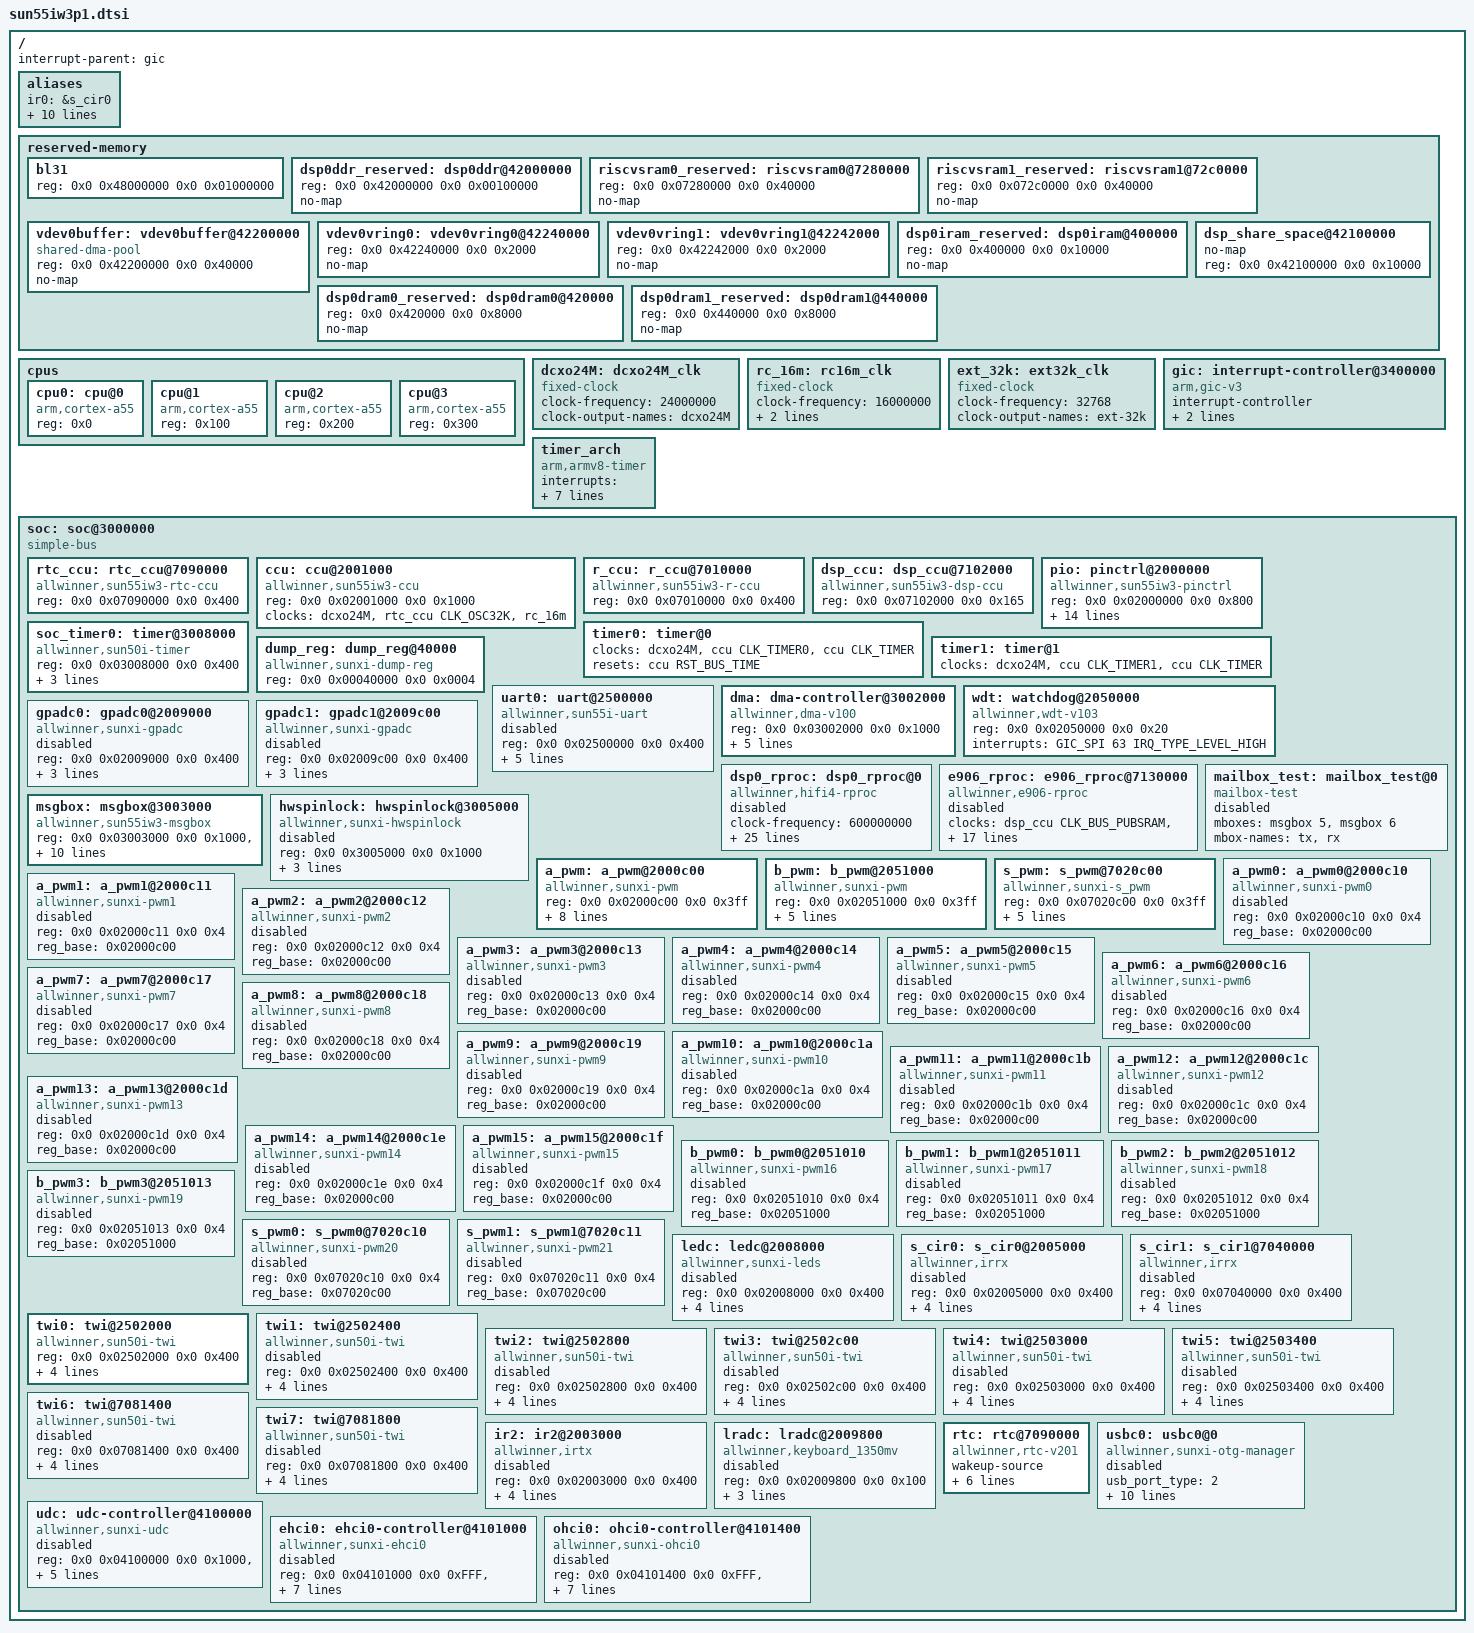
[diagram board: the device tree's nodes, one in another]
// SPDX-License-Identifier: (GPL-2.0+ or MIT)
/*
 * Copyright (C) 2021 liujuan1@allwinnertech.com
 */

#include <dt-bindings/clock/sun55iw3-ccu.h>
#include <dt-bindings/clock/sun55iw3-rtc.h>
#include <dt-bindings/clock/sun55iw3-r-ccu.h>
#include <dt-bindings/clock/sun55iw3-dsp-ccu.h>
#include <dt-bindings/gpio/gpio.h>
#include <dt-bindings/interrupt-controller/arm-gic.h>
#include <dt-bindings/reset/sun55iw3-ccu.h>
#include <dt-bindings/reset/sun55iw3-r-ccu.h>
#include <dt-bindings/reset/sun55iw3-dsp-ccu.h>

/ {
	interrupt-parent = <&gic>;
	#address-cells = <2>;
	#size-cells = <2>;

	aliases {
		ir0 = &s_cir0;
		ir1 = &s_cir1;
		ir2 = &ir2;
		twi0 = &twi0;
		twi1 = &twi1;
		twi2 = &twi2;
		twi3 = &twi3;
		twi4 = &twi4;
		twi5 = &twi5;
		twi6 = &twi6;
		twi7 = &twi7;
	};

	reserved-memory {
		#address-cells = <2>;
		#size-cells = <2>;
		ranges;

		bl31 {
			reg = <0x0 0x48000000 0x0 0x01000000>;
		};

		dsp0ddr_reserved: dsp0ddr@42000000 {
			reg = <0x0 0x42000000 0x0 0x00100000>;
			no-map;
		};

		riscvsram0_reserved: riscvsram0@7280000 {
			reg = <0x0 0x07280000 0x0 0x40000>;
			no-map;
		};

		riscvsram1_reserved: riscvsram1@72c0000 {
			reg = <0x0 0x072c0000 0x0 0x40000>;
			no-map;
		};

		/*
		 * The name should be "vdev%dbuffer".
		 * Its size should be not less than
		 *     RPMSG_BUF_SIZE * (num of buffers in a vring) * 2
		 *   = 512 * (num of buffers in a vring) * 2
		 */
		vdev0buffer: vdev0buffer@42200000 {
			compatible = "shared-dma-pool";
			reg = <0x0 0x42200000 0x0 0x40000>;
			no-map;
		};

		/*
		 * The name should be "vdev%dvring%d".
		 * The size of each should be not less than
		 *     PAGE_ALIGN(vring_size(num, align))
		 *   = PAGE_ALIGN(16 * num + 6 + 2 * num + (pads for align) + 6 + 8 * num)
		 *
		 * (Please refer to the vring layout in include/uapi/linux/virtio_ring.h)
		 */
		vdev0vring0: vdev0vring0@42240000 {
			reg = <0x0 0x42240000 0x0 0x2000>;
			no-map;
		};
		vdev0vring1: vdev0vring1@42242000 {
			reg = <0x0 0x42242000 0x0 0x2000>;
			no-map;
		};

		/*
		* dsp ram addr
		*/
		dsp0iram_reserved: dsp0iram@400000 {
			reg = <0x0 0x400000 0x0 0x10000>;
			no-map;
		};
		dsp0dram0_reserved: dsp0dram0@420000 {
			reg = <0x0 0x420000 0x0 0x8000>;
			no-map;
		};
		dsp0dram1_reserved: dsp0dram1@440000 {
			reg = <0x0 0x440000 0x0 0x8000>;
			no-map;
		};

		dsp_share_space@42100000 {
			no-map;
			reg = <0x0 0x42100000 0x0 0x10000>;
		};
	};

	cpus {
		#address-cells = <1>;
		#size-cells = <0>;

		cpu0: cpu@0 {
			device_type = "cpu";
			compatible = "arm,cortex-a55";
			reg = <0x0>;
		};

		cpu@1 {
			device_type = "cpu";
			compatible = "arm,cortex-a55";
			reg = <0x100>;
		};

		cpu@2 {
			device_type = "cpu";
			compatible = "arm,cortex-a55";
			reg = <0x200>;
		};

		cpu@3 {
			device_type = "cpu";
			compatible = "arm,cortex-a55";
			reg = <0x300>;
		};
	};

	dcxo24M: dcxo24M_clk {
		#clock-cells = <0>;
		compatible = "fixed-clock";
		clock-frequency = <24000000>;
		clock-output-names = "dcxo24M";
	};

	rc_16m: rc16m_clk {
		#clock-cells = <0>;
		compatible = "fixed-clock";
		clock-frequency = <16000000>;
		clock-accuracy = <300000000>;
		clock-output-names = "rc-16m";
	};

	ext_32k: ext32k_clk {
		#clock-cells = <0>;
		compatible = "fixed-clock";
		clock-frequency = <32768>;
		clock-output-names = "ext-32k";
	};

	gic: interrupt-controller@3400000 {
		compatible = "arm,gic-v3";
		#interrupt-cells = <3>;
		#address-cells = <0>;
		interrupt-controller;
		reg = <0x0 0x03400000 0 0x10000>, /* GIC Dist */
		      <0x0 0x03460000 0 0xFF004>; /* GIC Re */
	};

	timer_arch {
		compatible = "arm,armv8-timer";
		interrupts = <GIC_PPI 13 (GIC_CPU_MASK_SIMPLE(4) | IRQ_TYPE_LEVEL_LOW)>,
			   <GIC_PPI 14 (GIC_CPU_MASK_SIMPLE(4) | IRQ_TYPE_LEVEL_LOW)>,
			   <GIC_PPI 11 (GIC_CPU_MASK_SIMPLE(4) | IRQ_TYPE_LEVEL_LOW)>,
			   <GIC_PPI 10 (GIC_CPU_MASK_SIMPLE(4) | IRQ_TYPE_LEVEL_LOW)>;
		clock-frequency = <24000000>;
		interrupt-parent = <&gic>;
		arm,no-tick-in-suspend;
	};

	soc: soc@3000000 {
		compatible = "simple-bus";
		#address-cells = <2>;
		#size-cells = <2>;
		ranges;

		rtc_ccu: rtc_ccu@7090000 {
			compatible = "allwinner,sun55iw3-rtc-ccu";
			reg = <0x0 0x07090000 0x0 0x400>;
			#clock-cells = <1>;
			#reset-cells = <1>;
		};

		ccu: ccu@2001000 {
			compatible = "allwinner,sun55iw3-ccu";
			reg = <0x0 0x02001000 0x0 0x1000>;
			clocks = <&dcxo24M>, <&rtc_ccu CLK_OSC32K>, <&rc_16m>;
			clock-names = "hosc", "losc", "iosc";
			#clock-cells = <1>;
			#reset-cells = <1>;
		};

		r_ccu: r_ccu@7010000 {
			compatible = "allwinner,sun55iw3-r-ccu";
			reg = <0x0 0x07010000 0x0 0x400>;
			#clock-cells = <1>;
			#reset-cells = <1>;
		};

		dsp_ccu: dsp_ccu@7102000 {
			compatible = "allwinner,sun55iw3-dsp-ccu";
			reg = <0x0 0x07102000 0x0 0x165>;
			#clock-cells = <1>;
			#reset-cells = <1>;
		};

		pio: pinctrl@2000000 {
			compatible = "allwinner,sun55iw3-pinctrl";
			reg = <0x0 0x02000000 0x0 0x800>;
			interrupts = <GIC_SPI 67 IRQ_TYPE_LEVEL_HIGH>,
				     <GIC_SPI 69 IRQ_TYPE_LEVEL_HIGH>,
				     <GIC_SPI 71 IRQ_TYPE_LEVEL_HIGH>,
				     <GIC_SPI 73 IRQ_TYPE_LEVEL_HIGH>,
				     <GIC_SPI 75 IRQ_TYPE_LEVEL_HIGH>,
				     <GIC_SPI 77 IRQ_TYPE_LEVEL_HIGH>,
				     <GIC_SPI 79 IRQ_TYPE_LEVEL_HIGH>,
				     <GIC_SPI 81 IRQ_TYPE_LEVEL_HIGH>,
				     <GIC_SPI 83 IRQ_TYPE_LEVEL_HIGH>,
				     <GIC_SPI 85 IRQ_TYPE_LEVEL_HIGH>;
			clocks = <&ccu CLK_APB1>, <&dcxo24M>, <&rtc_ccu CLK_OSC32K>;
			clock-names = "apb", "hosc", "losc";
			gpio-controller;
			#gpio-cells = <3>;
			interrupt-controller;
			#interrupt-cells = <3>;

		};

		soc_timer0: timer@3008000 {
			compatible = "allwinner,sun50i-timer";
			device_type = "soc_timer";
			reg = <0x0 0x03008000 0x0 0x400>;
			interrupt-parent = <&gic>;
			interrupts = <GIC_SPI 55 IRQ_TYPE_LEVEL_HIGH>;
			sunxi-timers = <&timer0>, <&timer1>;
		};

		timer0: timer@0 {
			clocks = <&dcxo24M>, <&ccu CLK_TIMER0>, <&ccu CLK_TIMER>;
			clock-names = "parent", "mod", "bus";
			resets = <&ccu RST_BUS_TIME>;
		};

		timer1: timer@1 {
			clocks = <&dcxo24M>, <&ccu CLK_TIMER1>, <&ccu CLK_TIMER>;
			clock-names = "parent", "mod", "bus";
		};

		dump_reg:dump_reg@40000 {
			 compatible = "allwinner,sunxi-dump-reg";
			 reg = <0x0 0x00040000 0x0 0x0004>;
		};

		uart0: uart@2500000 {
			compatible = "allwinner,sun55i-uart";
			reg = <0x0 0x02500000 0x0 0x400>;
			interrupts = <GIC_SPI 2 IRQ_TYPE_LEVEL_HIGH>;
			clocks = <&ccu CLK_BUS_UART0>;
			resets = <&ccu RST_BUS_UART0>;
			uart0_port = <0>;
			uart0_type = <2>;
			status = "disabled";
		};

		dma:dma-controller@3002000 {
			compatible = "allwinner,dma-v100";
			reg = <0x0 0x03002000 0x0 0x1000>;
			interrupts = <GIC_SPI 50 IRQ_TYPE_LEVEL_HIGH>;
			clocks = <&ccu CLK_DMA>, <&ccu CLK_DMA_MBUS_GATE>;
			clock-names = "bus", "mbus";
			dma-channels = <16>;
			dma-requests = <54>;
			resets = <&ccu RST_BUS_DMA>;
			#dma-cells = <1>;
		};

		wdt: watchdog@2050000 {
			compatible = "allwinner,wdt-v103";
			reg = <0x0 0x02050000 0x0 0x20>;  /* In Timers Spec */
			interrupts = <GIC_SPI 63 IRQ_TYPE_LEVEL_HIGH>;  /* In GIC Spec */
		};

		gpadc0: gpadc0@2009000 {
			compatible = "allwinner,sunxi-gpadc";
			reg = <0x0 0x02009000 0x0 0x400>;
			interrupts = <GIC_SPI 61 IRQ_TYPE_LEVEL_HIGH>;
			clocks = <&ccu CLK_BUS_GPADC0>;
			clock-names = "bus";
			resets = <&ccu RST_BUS_GPADC0>;
			status = "disabled";
		};

		gpadc1: gpadc1@2009c00 {
			compatible = "allwinner,sunxi-gpadc";
			reg = <0x0 0x02009c00 0x0 0x400>;
			interrupts = <GIC_SPI 64 IRQ_TYPE_LEVEL_HIGH>;
			clocks = <&ccu CLK_BUS_GPADC1>;
			clock-names = "bus";
			resets = <&ccu RST_BUS_GPADC1>;
			status = "disabled";
		};

		dsp0_rproc: dsp0_rproc@0 {
			compatible = "allwinner,hifi4-rproc";
			clock-frequency = <600000000>;
			clocks = <&ccu CLK_PLL_PERI0_2X>, <&ccu CLK_DSP>, <&dsp_ccu CLK_BUS_DSP_CFG>, <&r_ccu CLK_R_AHB>;
			clock-names = "pll", "mod", "cfg", "ahbs";
			resets = <&dsp_ccu RST_BUS_DSP>, <&dsp_ccu RST_BUS_DSP_CFG>, <&dsp_ccu RST_BUS_DSP_DBG>;
			reset-names = "mod-rst", "cfg-rst", "dbg-rst";
			reg = <0x0 0x07010364 0x0 0x04>,
				<0x0 0x07100000 0x0 0x40>;
			reg-names = "sram-for-cpux", "hifi4-cfg";
			mboxes = <&msgbox 4>;
			mbox-names = "arm-kick";
			memory-region = <&dsp0ddr_reserved>, <&vdev0buffer>, <&vdev0vring0>, <&vdev0vring1>,
					<&dsp0iram_reserved>, <&dsp0dram0_reserved>, <&dsp0dram1_reserved>;
			memory-mappings =
				/* < DA		len		PA >	*/
				/* local SRAM via external bus */
				< 0x20000	0x20000		0x20000 >,
				/* local SRAM via internal bus */
				< 0x400000	0x10000		0x400000 >,
				< 0x420000	0x8000		0x420000 >,
				< 0x440000	0x8000		0x440000 >,
				/* DDR front 256MB */
				< 0x10000000	0x10000000	0x40000000 >,
				/* local SRAM via internal bus */
				< 0x20020000	0x10000		0x400000 >,
				< 0x20030000	0x8000		0x420000 >,
				< 0x20038000	0x8000		0x440000 >,

				/* DDR front 256MB */
				< 0x30000000	0x10000000	0x40000000 >,
				/* DDR front 1GB */
				< 0x40000000	0x40000000	0x40000000 >,
				/* DDR front 1GB */
				< 0x80000000	0x40000000	0x40000000 >,
				/* DDR front 1GB */
				< 0xC0000000	0x40000000	0x40000000 >;
			id = <0>;
			status = "disabled";
		};

		e906_rproc: e906_rproc@7130000 {
			compatible = "allwinner,e906-rproc";
			clocks = <&dsp_ccu CLK_BUS_PUBSRAM>, <&dsp_ccu CLK_BUS_RV>, <&dsp_ccu CLK_BUS_RV_CFG>;
			clock-names = "pubsram", "mod", "cfg";
			resets = <&dsp_ccu RST_BUS_PUBSRAM>, <&dsp_ccu RST_BUS_RV>, <&dsp_ccu RST_BUS_RV_CFG>, <&dsp_ccu RST_BUS_RV_DBG>;
			reset-names = "pubsram-rst", "mod-rst", "cfg-rst", "dbg-rst";
			reg = <0x0 0x07130000 0x0 0x1000>;
			reg-names = "e906-cfg";
			mboxes = <&msgbox 8>;
			mbox-names = "arm-kick";
			memory-region = <&riscvsram0_reserved>, <&riscvsram1_reserved>, <&vdev0buffer>, <&vdev0vring0>, <&vdev0vring1>;
			memory-mappings =
				/* < DA		len		PA >	*/
				/* DSP RAM */
				< 0x20000	0x20000		0x20000 >,
				/* SRAM A2 */
				< 0x40000	0x24000		0x40000 >,
				/* DDR */
				< 0x8000000	0x37f00000	0x8000000 >,
				/* SRAM SPACE 0 */
				< 0x3ffc0000	0x40000		0x07280000 >,
				/* SRAM SPACE 1 */
				< 0x40000000	0x40000		0x072c0000 >,
				/* DRAM SPACE */
				< 0x40040000	0x3ffc0000	0x40040000>;
			id = <0>;
			status = "disabled";
		};

		/* test for AMP mailbox */
		mailbox_test: mailbox_test@0 {
			compatible = "mailbox-test";
			mboxes = <&msgbox 5>, <&msgbox 6>;
			mbox-names = "tx", "rx";
			status = "disabled";
		};

		/*
		* Some bitfile doesn't have riscv part.
		* When use such bitfile, remember to delete
		* riscv reg and irq in msgbox dts node,
		* otherwise may cause Linux stuck.
		* In the same time, adjust sun55iw3 hwdata's
		* processors_max to 3, and mbox_num_chans to 8
		* in msgbox driver.
		*/
		msgbox: msgbox@3003000 {
			compatible = "allwinner,sun55iw3-msgbox";
			#mbox-cells = <1>;
			reg = <0x0 0x03003000 0x0 0x1000>,
			      <0x0 0x07120000 0x0 0x1000>,
			      <0x0 0x07094000 0x0 0x1000>,
			      <0x0 0x07136000 0x0 0x1000>;
			interrupts = <GIC_SPI 0 IRQ_TYPE_LEVEL_HIGH>,
					<GIC_SPI 1 IRQ_TYPE_LEVEL_HIGH>,
					<GIC_SPI 181 IRQ_TYPE_LEVEL_HIGH>,
					<GIC_SPI 174 IRQ_TYPE_LEVEL_HIGH>;
			clocks = <&ccu CLK_MSGBOX0>;
			resets = <&ccu RST_BUS_MSGBOX0>;
			reset-names = "rst";
			local_id = <0>;
		};

		hwspinlock: hwspinlock@3005000 {
			compatible = "allwinner,sunxi-hwspinlock";
			reg = <0x0 0x3005000 0x0 0x1000>;
			#hwlock-cells = <1>;
			clocks = <&ccu CLK_SPINLOCK>;
			clock-names = "clk_hwspinlock_bus";
			resets = <&ccu RST_BUS_SPINLOCK>;
			reset-names = "rst";
			num-locks = <32>;
			status = "disabled";
		};

		a_pwm: a_pwm@2000c00 {
			#pwm-cells = <0x3>;
			compatible = "allwinner,sunxi-pwm";
			reg = <0x0 0x02000c00 0x0 0x3ff>;
			clocks = <&ccu CLK_PWM>;
			resets = <&ccu RST_BUS_PWM>;
			pwm-number = <16>;
			pwm-base = <0x0>;
			sunxi-pwms = <&a_pwm0>, <&a_pwm1>, <&a_pwm2>, <&a_pwm3>, <&a_pwm4>,
			<&a_pwm5>, <&a_pwm6>, <&a_pwm7>, <&a_pwm8>, <&a_pwm9>,
			<&a_pwm10>, <&a_pwm11>, <&a_pwm12>, <&a_pwm13>,
			<&a_pwm14>, <&a_pwm15>;
		};

		b_pwm: b_pwm@2051000 {
			#pwm-cells = <0x3>;
			compatible = "allwinner,sunxi-pwm";
			reg = <0x0 0x02051000 0x0 0x3ff>;
			clocks = <&ccu CLK_PWM1>;
			resets = <&ccu RST_BUS_PWM1>;
			pwm-number = <4>;
			pwm-base = <0x10>;
			sunxi-pwms = <&b_pwm0>, <&b_pwm1>, <&b_pwm2>, <&b_pwm3>;
		};

		s_pwm: s_pwm@7020c00 {
			#pwm-cells = <0x3>;
			compatible = "allwinner,sunxi-s_pwm";
			reg = <0x0 0x07020c00 0x0 0x3ff>;
			clocks = <&r_ccu CLK_R_PWM>;
			resets = <&r_ccu RST_R_PWM>;
			pwm-number = <2>;
			pwm-base = <0x20>;
			sunxi-pwms = <&s_pwm0>, <&s_pwm1>;
		};

		a_pwm0: a_pwm0@2000c10 {
			compatible = "allwinner,sunxi-pwm0";
			pinctrl-names = "active", "sleep";
			reg = <0x0 0x02000c10 0x0 0x4>;
			reg_base = <0x02000c00>;
			status = "disabled";
		};

		a_pwm1: a_pwm1@2000c11 {
			compatible = "allwinner,sunxi-pwm1";
			pinctrl-names = "active", "sleep";
			reg = <0x0 0x02000c11 0x0 0x4>;
			reg_base = <0x02000c00>;
			status = "disabled";
		};

		a_pwm2: a_pwm2@2000c12 {
			compatible = "allwinner,sunxi-pwm2";
			pinctrl-names = "active", "sleep";
			reg = <0x0 0x02000c12 0x0 0x4>;
			reg_base = <0x02000c00>;
			status = "disabled";
		};

		a_pwm3: a_pwm3@2000c13 {
			compatible = "allwinner,sunxi-pwm3";
			pinctrl-names = "active", "sleep";
			reg = <0x0 0x02000c13 0x0 0x4>;
			reg_base = <0x02000c00>;
			status = "disabled";
		};

		a_pwm4: a_pwm4@2000c14 {
			compatible = "allwinner,sunxi-pwm4";
			pinctrl-names = "active", "sleep";
			reg = <0x0 0x02000c14 0x0 0x4>;
			reg_base = <0x02000c00>;
			status = "disabled";
		};

		a_pwm5: a_pwm5@2000c15 {
			compatible = "allwinner,sunxi-pwm5";
			pinctrl-names = "active", "sleep";
			reg = <0x0 0x02000c15 0x0 0x4>;
			reg_base = <0x02000c00>;
			status = "disabled";
		};

		a_pwm6: a_pwm6@2000c16 {
			compatible = "allwinner,sunxi-pwm6";
			pinctrl-names = "active", "sleep";
			reg = <0x0 0x02000c16 0x0 0x4>;
			reg_base = <0x02000c00>;
			status = "disabled";
		};

		a_pwm7: a_pwm7@2000c17 {
			compatible = "allwinner,sunxi-pwm7";
			pinctrl-names = "active", "sleep";
			reg = <0x0 0x02000c17 0x0 0x4>;
			reg_base = <0x02000c00>;
			status = "disabled";
		};

		a_pwm8: a_pwm8@2000c18 {
			compatible = "allwinner,sunxi-pwm8";
			pinctrl-names = "active", "sleep";
			reg = <0x0 0x02000c18 0x0 0x4>;
			reg_base = <0x02000c00>;
			status = "disabled";
		};

		a_pwm9: a_pwm9@2000c19 {
			compatible = "allwinner,sunxi-pwm9";
			pinctrl-names = "active", "sleep";
			reg = <0x0 0x02000c19 0x0 0x4>;
			reg_base = <0x02000c00>;
			status = "disabled";
		};

		a_pwm10: a_pwm10@2000c1a {
			compatible = "allwinner,sunxi-pwm10";
			pinctrl-names = "active", "sleep";
			reg = <0x0 0x02000c1a 0x0 0x4>;
			reg_base = <0x02000c00>;
			status = "disabled";
		};

		a_pwm11: a_pwm11@2000c1b {
			compatible = "allwinner,sunxi-pwm11";
			pinctrl-names = "active", "sleep";
			reg = <0x0 0x02000c1b 0x0 0x4>;
			reg_base = <0x02000c00>;
			status = "disabled";
		};

		a_pwm12: a_pwm12@2000c1c {
			compatible = "allwinner,sunxi-pwm12";
			pinctrl-names = "active", "sleep";
			reg = <0x0 0x02000c1c 0x0 0x4>;
			reg_base = <0x02000c00>;
			status = "disabled";
		};

		a_pwm13: a_pwm13@2000c1d {
			compatible = "allwinner,sunxi-pwm13";
			pinctrl-names = "active", "sleep";
			reg = <0x0 0x02000c1d 0x0 0x4>;
			reg_base = <0x02000c00>;
			status = "disabled";
		};

		a_pwm14: a_pwm14@2000c1e {
			compatible = "allwinner,sunxi-pwm14";
			pinctrl-names = "active", "sleep";
			reg = <0x0 0x02000c1e 0x0 0x4>;
			reg_base = <0x02000c00>;
			status = "disabled";
		};

		a_pwm15: a_pwm15@2000c1f {
			compatible = "allwinner,sunxi-pwm15";
			pinctrl-names = "active", "sleep";
			reg = <0x0 0x02000c1f 0x0 0x4>;
			reg_base = <0x02000c00>;
			status = "disabled";
		};

		b_pwm0: b_pwm0@2051010 {
			compatible = "allwinner,sunxi-pwm16";
			pinctrl-names = "active", "sleep";
			reg = <0x0 0x02051010 0x0 0x4>;
			reg_base = <0x02051000>;
			status = "disabled";
		};

		b_pwm1: b_pwm1@2051011 {
			compatible = "allwinner,sunxi-pwm17";
			pinctrl-names = "active", "sleep";
			reg = <0x0 0x02051011 0x0 0x4>;
			reg_base = <0x02051000>;
			status = "disabled";
		};

		b_pwm2: b_pwm2@2051012 {
			compatible = "allwinner,sunxi-pwm18";
			pinctrl-names = "active", "sleep";
			reg = <0x0 0x02051012 0x0 0x4>;
			reg_base = <0x02051000>;
			status = "disabled";
		};

		b_pwm3: b_pwm3@2051013 {
			compatible = "allwinner,sunxi-pwm19";
			pinctrl-names = "active", "sleep";
			reg = <0x0 0x02051013 0x0 0x4>;
			reg_base = <0x02051000>;
			status = "disabled";
		};

		s_pwm0: s_pwm0@7020c10 {
			compatible = "allwinner,sunxi-pwm20";
			pinctrl-names = "active", "sleep";
			reg = <0x0 0x07020c10 0x0 0x4>;
			reg_base = <0x07020c00>;
			status = "disabled";
		};

		s_pwm1: s_pwm1@7020c11 {
			compatible = "allwinner,sunxi-pwm21";
			pinctrl-names = "active", "sleep";
			reg = <0x0 0x07020c11 0x0 0x4>;
			reg_base = <0x07020c00>;
			status = "disabled";
		};

		ledc: ledc@2008000 {
			#address-cells = <1>;
			#size-cells = <0>;
			compatible = "allwinner,sunxi-leds";
			reg = <0x0 0x02008000 0x0 0x400>;
			interrupts = <GIC_SPI 28 IRQ_TYPE_LEVEL_HIGH>;
			clocks = <&ccu CLK_LEDC>, <&ccu CLK_BUS_LEDC>;
			clock-names = "clk_ledc", "clk_cpuapb";
			resets = <&ccu RST_BUS_LEDC>;
			reset-names = "ledc_reset";
			dmas = <&dma 42>, <&dma 42>;
			dma-names = "rx", "tx";
			status = "disabled";
		};

		s_cir0: s_cir0@2005000 {
			compatible = "allwinner,irrx";
			reg = <0x0 0x02005000 0x0 0x400>;
			interrupts = <GIC_SPI 27 IRQ_TYPE_LEVEL_HIGH>;
			clocks = <&ccu CLK_BUS_IRRX>, <&dcxo24M>, <&ccu CLK_IRRX>;
			clock-names = "bus", "pclk", "mclk";
			resets = <&ccu RST_BUS_IRRX>;
			status = "disabled";
		};

		s_cir1: s_cir1@7040000 {
			compatible = "allwinner,irrx";
			reg = <0x0 0x07040000 0x0 0x400>;
			interrupts = <GIC_SPI 167 IRQ_TYPE_LEVEL_HIGH>;
			clocks = <&r_ccu CLK_BUS_R_IRRX>, <&dcxo24M>, <&r_ccu CLK_R_IRRX>;
			clock-names = "bus", "pclk", "mclk";
			resets = <&r_ccu RST_R_IRRX>;
			status = "disabled";
		};

		twi0: twi@2502000 {
			#address-cells = <1>;
			#size-cells = <0>;
			compatible = "allwinner,sun50i-twi";
			device_type = "twi0";
			reg = <0x0 0x02502000 0x0 0x400>;
			interrupts = <GIC_SPI 10 IRQ_TYPE_LEVEL_HIGH>;
			clocks = <&ccu CLK_TWI0>;
			clock-names = "bus";
			resets = <&ccu RST_BUS_TWI0>;
			dmas = <&dma 43>, <&dma 43>;
			dma-names = "tx", "rx";
			status = "okay";
		};

		twi1: twi@2502400 {
			#address-cells = <1>;
			#size-cells = <0>;
			compatible = "allwinner,sun50i-twi";
			device_type = "twi1";
			reg = <0x0 0x02502400 0x0 0x400>;
			interrupts = <GIC_SPI 11 IRQ_TYPE_LEVEL_HIGH>;
			clocks = <&ccu CLK_TWI1>;
			clock-names = "bus";
			resets = <&ccu RST_BUS_TWI1>;
			dmas = <&dma 44>, <&dma 44>;
			dma-names = "tx", "rx";
			status = "disabled";
		};

		twi2: twi@2502800 {
			#address-cells = <1>;
			#size-cells = <0>;
			compatible = "allwinner,sun50i-twi";
			device_type = "twi2";
			reg = <0x0 0x02502800 0x0 0x400>;
			interrupts = <GIC_SPI 12 IRQ_TYPE_LEVEL_HIGH>;
			clocks = <&ccu CLK_TWI2>;
			clock-names = "bus";
			resets = <&ccu RST_BUS_TWI2>;
			dmas = <&dma 45>, <&dma 45>;
			dma-names = "tx", "rx";
			status = "disabled";
		};

		twi3: twi@2502c00 {
			#address-cells = <1>;
			#size-cells = <0>;
			compatible = "allwinner,sun50i-twi";
			device_type = "twi3";
			reg = <0x0 0x02502c00 0x0 0x400>;
			interrupts = <GIC_SPI 13 IRQ_TYPE_LEVEL_HIGH>;
			clocks = <&ccu CLK_TWI3>;
			clock-names = "bus";
			resets = <&ccu RST_BUS_TWI3>;
			dmas = <&dma 46>, <&dma 46>;
			dma-names = "tx", "rx";
			status = "disabled";
		};

		twi4: twi@2503000 {
			#address-cells = <1>;
			#size-cells = <0>;
			compatible = "allwinner,sun50i-twi";
			device_type = "twi4";
			reg = <0x0 0x02503000 0x0 0x400>;
			interrupts = <GIC_SPI 14 IRQ_TYPE_LEVEL_HIGH>;
			clocks = <&ccu CLK_TWI4>;
			clock-names = "bus";
			resets = <&ccu RST_BUS_TWI4>;
			dmas = <&dma 47>, <&dma 47>;
			dma-names = "tx", "rx";
			status = "disabled";
		};

		twi5: twi@2503400{
			#address-cells = <1>;
			#size-cells = <0>;
			compatible = "allwinner,sun50i-twi";
			device_type = "twi5";
			reg = <0x0 0x02503400 0x0 0x400>;
			interrupts = <GIC_SPI 15 IRQ_TYPE_LEVEL_HIGH>;
			clocks = <&ccu CLK_TWI5>;
			clock-names = "bus";
			resets = <&ccu RST_BUS_TWI5>;
			dmas = <&dma 48>, <&dma 48>;
			dma-names = "tx", "rx";
			status = "disabled";
		};

		twi6: twi@7081400 {
			#address-cells = <1>;
			#size-cells = <0>;
			compatible = "allwinner,sun50i-twi";
			device_type = "twi6";
			reg = <0x0 0x07081400 0x0 0x400>;
			interrupts = <GIC_SPI 164 IRQ_TYPE_LEVEL_HIGH>;
			clocks = <&r_ccu CLK_BUS_R_TWI0>;
			clock-names = "bus";
			resets = <&r_ccu RST_R_TWI0>;
			dmas = <&dma 49>, <&dma 49>;
			dma-names = "tx", "rx";
			status = "disabled";
		};

		twi7: twi@7081800 {
			#address-cells = <1>;
			#size-cells = <0>;
			compatible = "allwinner,sun50i-twi";
			device_type = "twi7";
			reg = <0x0 0x07081800 0x0 0x400>;
			interrupts = <GIC_SPI 165 IRQ_TYPE_LEVEL_HIGH>;
			clocks = <&r_ccu CLK_BUS_R_TWI1>;
			clock-names = "bus";
			resets = <&r_ccu RST_R_TWI1>;
			dmas = <&dma 50>, <&dma 50>;
			dma-names = "tx", "rx";
			status = "disabled";
		};

		ir2: ir2@2003000 {
			compatible = "allwinner,irtx";
			reg = <0x0 0x02003000 0x0 0x400>;
			interrupts = <GIC_SPI 26 IRQ_TYPE_LEVEL_HIGH>;
			clocks = <&ccu CLK_BUS_IRTX>, <&dcxo24M>, <&ccu CLK_IRTX>;
			clock-names = "bus", "pclk", "mclk";
			resets = <&ccu RST_BUS_IRTX>;
			status = "disabled";
		};

		lradc: lradc@2009800 {
			compatible = "allwinner,keyboard_1350mv";
			reg = <0x0 0x02009800 0x0 0x100>;
			interrupts = <GIC_SPI 66 IRQ_TYPE_NONE>;
			clocks = <&ccu CLK_LRADC>;
			resets = <&ccu RST_BUS_LRADC>;
			status = "disabled";
		};

		rtc: rtc@7090000 {
			compatible = "allwinner,rtc-v201";
			device_type = "rtc";
			wakeup-source;
			reg = <0x0 0x07090000 0x0 0x320>;
			interrupts = <GIC_SPI 157 IRQ_TYPE_LEVEL_HIGH>;
			clocks = <&r_ccu CLK_BUS_R_RTC>, <&rtc_ccu CLK_RTC_1K>, <&rtc_ccu CLK_RTC_SPI>;
			clock-names = "r-ahb-rtc", "rtc-1k", "rtc-spi";
			resets = <&r_ccu RST_R_RTC>;
			gpr_cur_pos = <6>;
		};

		usbc0:usbc0@0 {
			device_type = "usbc0";
			compatible = "allwinner,sunxi-otg-manager";
			usb_port_type = <2>;
			usb_detect_type = <1>;
			usb_detect_mode = <0>;
			usb_id_gpio;
			usb_det_vbus_gpio;
			usb_regulator_io = "nocare";
			usb_wakeup_suspend = <0>;
			usb_luns = <3>;
			usb_serial_unique = <0>;
			usb_serial_number = "20080411";
			rndis_wceis = <1>;
			status = "disabled";
		};

		udc:udc-controller@4100000 {
			compatible = "allwinner,sunxi-udc";
			reg = <0x0 0x04100000 0x0 0x1000>, /*udc base*/
			      <0x0 0x00000000 0x0 0x100>; /*sram base*/
			interrupts = <GIC_SPI 29 IRQ_TYPE_LEVEL_HIGH>;
			clocks = <&ccu CLK_USBOTG0>;
			clock-names = "bus_otg";
			resets = <&ccu RST_USB_OTG0>, <&ccu RST_USB_PHY0_RSTN>;
			reset-names = "otg", "phy";
			status = "disabled";
		};

		ehci0:ehci0-controller@4101000 {
			compatible = "allwinner,sunxi-ehci0";
			reg = <0x0 0x04101000 0x0 0xFFF>, /*hci0 base*/
			      <0x0 0x00000000 0x0 0x100>, /*sram base*/
			      <0x0 0x04100000 0x0 0x1000>; /*otg base*/
			interrupts = <GIC_SPI 30 IRQ_TYPE_LEVEL_HIGH>;
			clocks = <&ccu CLK_USBEHCI0>;
			clock-names = "bus_hci";
			resets = <&ccu RST_USB_EHCI0>, <&ccu RST_USB_PHY0_RSTN>;
			reset-names = "hci", "phy";
			hci_ctrl_no = <0>;
			status = "disabled";
		};

		ohci0:ohci0-controller@4101400 {
			compatible = "allwinner,sunxi-ohci0";
			reg = <0x0 0x04101400 0x0 0xFFF>, /*hci0 base*/
			      <0x0 0x00000000 0x0 0x100>, /*sram base*/
			      <0x0 0x04100000 0x0 0x1000>; /*otg base*/
			interrupts = <GIC_SPI 31 IRQ_TYPE_LEVEL_HIGH>;
			clocks = <&ccu CLK_USBOHCI0>, <&ccu CLK_USB0>;
			clock-names = "bus_hci", "ohci";
			resets = <&ccu RST_USB_OHCI0>, <&ccu RST_USB_PHY0_RSTN>;
			reset-names = "hci", "phy";
			hci_ctrl_no = <0>;
			status = "disabled";
		};

	};
};

